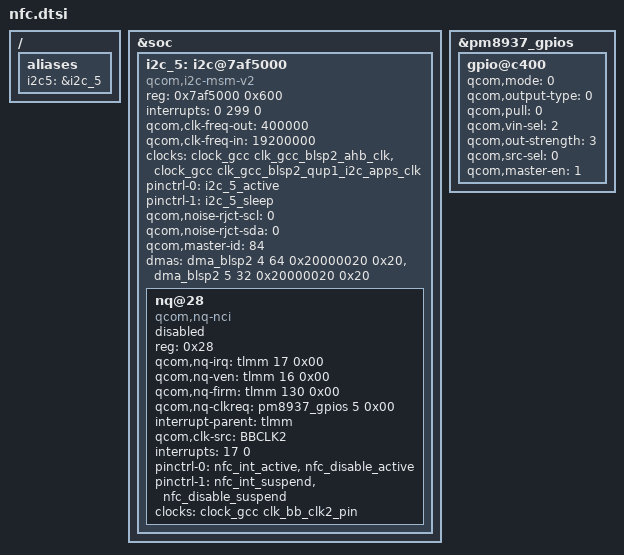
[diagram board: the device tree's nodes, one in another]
/ {
	aliases {
		i2c5 = &i2c_5;
	};
};

&soc {
	i2c_5: i2c@7af5000 { /* BLSP2 QUP1 */
		status = "okay";
		compatible = "qcom,i2c-msm-v2";
		#address-cells = <1>;
		#size-cells = <0>;
		reg-names = "qup_phys_addr";
		reg = <0x7af5000 0x600>;
		interrupt-names = "qup_irq";
		interrupts = <0 299 0>;
		qcom,clk-freq-out = <400000>;
		qcom,clk-freq-in  = <19200000>;
		clock-names = "iface_clk", "core_clk";
		clocks = <&clock_gcc clk_gcc_blsp2_ahb_clk>,
			<&clock_gcc clk_gcc_blsp2_qup1_i2c_apps_clk>;

		pinctrl-names = "i2c_active", "i2c_sleep";
		pinctrl-0 = <&i2c_5_active>;
		pinctrl-1 = <&i2c_5_sleep>;
		qcom,noise-rjct-scl = <0>;
		qcom,noise-rjct-sda = <0>;
		qcom,master-id = <84>;
		dmas = <&dma_blsp2 4 64 0x20000020 0x20>,
			<&dma_blsp2 5 32 0x20000020 0x20>;
		dma-names = "tx", "rx";
	};
};

&i2c_5 {
	nq@28 {
		compatible = "qcom,nq-nci";
		status = "/chosen", "mmi,nfc", "true";
		reg = <0x28>;
		qcom,nq-irq = <&tlmm 17 0x00>;
		qcom,nq-ven = <&tlmm 16 0x00>;
		qcom,nq-firm = <&tlmm 130 0x00>;
		qcom,nq-clkreq = <&pm8937_gpios 5 0x00>;
		interrupt-parent = <&tlmm>;
		qcom,clk-src = "BBCLK2";
		interrupts = <17 0>;
		interrupt-names = "nfc_irq";
		pinctrl-names = "nfc_active", "nfc_suspend";
		pinctrl-0 = <&nfc_int_active &nfc_disable_active>;
		pinctrl-1 = <&nfc_int_suspend &nfc_disable_suspend>;
		clocks = <&clock_gcc clk_bb_clk2_pin>;
		clock-names = "ref_clk";
	};
};

&pm8937_gpios {
	gpio@c400 {
		qcom,mode = <0>;
		qcom,output-type = <0>;
		qcom,pull = <0>;
		qcom,vin-sel = <2>;
		qcom,out-strength = <3>;
		qcom,src-sel = <0>;
		qcom,master-en = <1>;
		status = "ok";
	};
};
